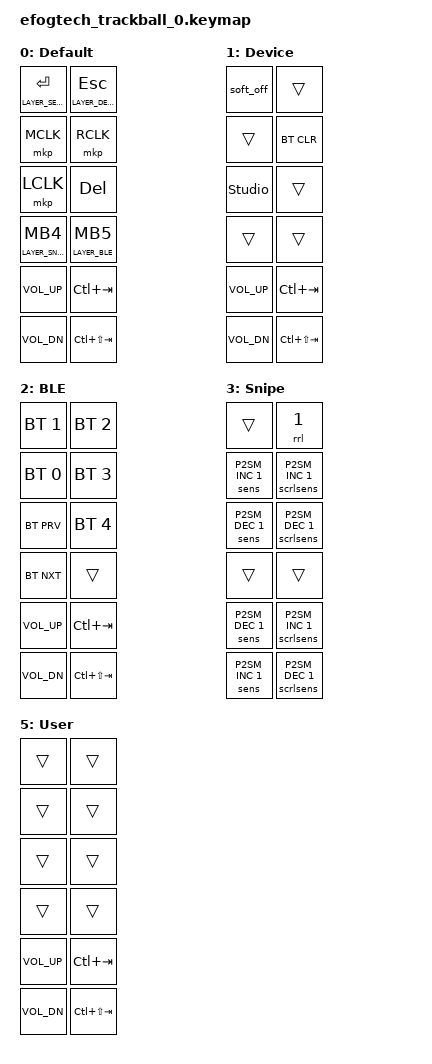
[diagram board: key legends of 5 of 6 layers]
#include <behaviors.dtsi>
#include <dt-bindings/zmk/bt.h>
#include <dt-bindings/zmk/keys.h>
#include <dt-bindings/zmk/pointing.h>
#include <dt-bindings/zmk/outputs.h>
#include <dt-bindings/zmk/adaptive_feedback.h>
#include <dt-bindings/zmk/bistable_behavior.h>
#include <dt-bindings/zmk/p2sm.h>

#ifdef  LAYER_DEFAULT
#undef  LAYER_DEFAULT
#endif
#define LAYER_DEFAULT  0

#ifdef  LAYER_DEVICE
#undef  LAYER_DEVICE
#endif
#define LAYER_DEVICE   1

#ifdef  LAYER_BLE
#undef  LAYER_BLE
#endif
#define LAYER_BLE      2

#ifdef  LAYER_SNIPE
#undef  LAYER_SNIPE
#endif
#define LAYER_SNIPE    3

#ifdef  LAYER_SETTINGS
#undef  LAYER_SETTINGS
#endif
#define LAYER_SETTINGS 4

#ifdef  LAYER_USER
#undef  LAYER_USER
#endif
#define LAYER_USER     5

/ {
    keymap {
        compatible = "zmk,keymap";

        layer_default {
            display-name = "Default";
            DECLARE_ENCODERS;
            bindings = <
                // buttons
                &ltmkp LAYER_SETTINGS ENTER       &ltmkp LAYER_DEVICE ESC

                &mkp MCLK                         &mkp RCLK
                &mkp LCLK                         &kp  DELETE

                &ltm LAYER_SNIPE  MB4             &ltm LAYER_BLE MB5

                // rotary encoders
                &kp C_VOL_UP                      &kp LC(TAB)
                &kp C_VOL_DN                      &kp LC(LS(TAB))
            >;
        };

        layer1 {
            display-name = "Device";
            DECLARE_ENCODERS;
            bindings = <
                &soft_off                       &trans

                &trans                          &bt BT_CLR
                &studio_unlock                  &trans

                &trans                          &trans

                &kp C_VOL_UP                    &kp LC(TAB)
                &kp C_VOL_DN                    &kp LC(LS(TAB))
            >;
        };

        layer2 {
            display-name = "BLE";
            DECLARE_ENCODERS;
            bindings = <
                &bt BT_SEL 1                    &bt BT_SEL 2

                &bt BT_SEL 0                    &bt BT_SEL 3
                &bt BT_PRV                      &bt BT_SEL 4

                &bt BT_NXT                      &trans

                &kp C_VOL_UP                    &kp LC(TAB)
                &kp C_VOL_DN                    &kp LC(LS(TAB))
            >;
        };

        layer3 {
            display-name = "Snipe";
            DECLARE_ENCODERS;
            bindings = <
                &trans                          &rrl 1

                &sens   P2SM_INC 1              &scrlsens    P2SM_INC 1
                &sens   P2SM_DEC 1              &scrlsens    P2SM_DEC 1

                &trans                          &trans

                &sens P2SM_DEC 1                &scrlsens P2SM_INC 1
                &sens P2SM_INC 1                &scrlsens P2SM_DEC 1
            >;
        };

        layer4 {
            display-name = "Setting";
            DECLARE_ENCODERS;
            bindings = <
                // &trans                           &rgb_ug RBG_OFF
                &trans                           &trans
                &trans                           &trans

                &trans                           &trans
                &trans                           &trans
                // &rgb_ug RGB_TOG                  &trans
                // &rgb_ug RGB_EFF                  &trans

                &trans                           &trans

                &kp LEFT                         &kp RIGHT
                &kp RIGHT                        &kp LEFT
            >;
        };

        layer5 {
            display-name = "User";
            DECLARE_ENCODERS;
            bindings = <
                &trans        &trans
                &trans        &trans
                &trans        &trans
                &trans        &trans

                &kp C_VOL_UP                    &kp LC(TAB)
                &kp C_VOL_DN                    &kp LC(LS(TAB))
            >;
        };
    };

    trackball {
		input-processors = <&zip_bistable_twist_scaler>,
						   <&zip_pointer_accel>, <&zip_scroll_accel>,
						   <&zip_rotate_pointer>, <&zip_rotate_scroll>,
						   <&esb_ip>, <&zip_ble_report_rate_limit>;

		scroll {
			layers = <LAYER_USER>;
			input-processors = <&zip_bistable_scroll_xy_scaler>, <&zip_axis_clamper>,
							   <&zip_xy_to_scroll_mapper>, <&zip_scroll_transform INPUT_TRANSFORM_Y_INVERT>,
							   <&zip_dragscroll_accel>, <&zip_rotate_scroll>,
							   <&esb_ip>, <&zip_ble_report_rate_limit>;
		};

        snipe {
            layers = <LAYER_SNIPE>;
			input-processors = <&zip_bistable_snipe_scaler>,
							   <&zip_rotate_pointer>, <&zip_rotate_scroll>,
							   <&esb_ip>, <&zip_ble_report_rate_limit>;
        };
    };
};
